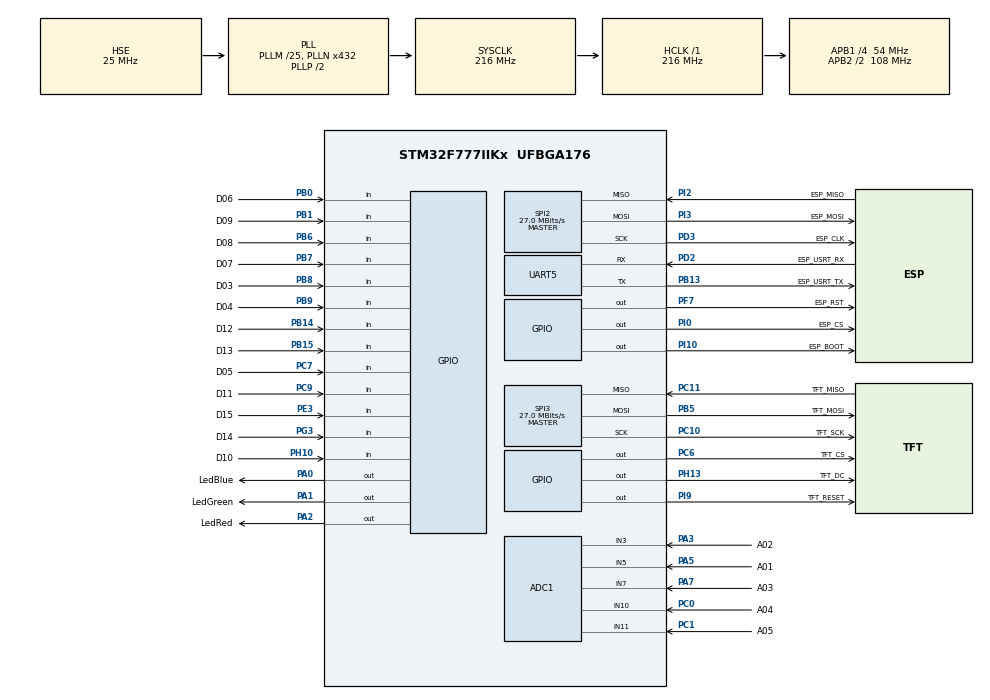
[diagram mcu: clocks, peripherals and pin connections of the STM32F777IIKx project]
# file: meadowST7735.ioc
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ADC1.Channel-0\#ChannelRegularConversion=ADC_CHANNEL_5
ADC1.NbrOfConversionFlag=1
ADC1.Rank-0\#ChannelRegularConversion=1
ADC1.SamplingTime-0\#ChannelRegularConversion=ADC_SAMPLETIME_3CYCLES
ADC1.master=1
CORTEX_M7.ART_ACCLERATOR_ENABLE=1
CORTEX_M7.PREFETCH_ENABLE=0
Mcu.Family=STM32F7
Mcu.Name=STM32F777IIKx
Mcu.Package=UFBGA176
NVIC.PriorityGroup=NVIC_PRIORITYGROUP_4
PA0/WKUP.GPIO_Label=LedBlue
PA0/WKUP.Signal=GPIO_Output
PA1.GPIO_Label=LedGreen
PA1.Signal=GPIO_Output
PA13.Mode=Serial_Wire
PA13.Signal=SYS_JTMS-SWDIO
PA14.Mode=Serial_Wire
PA14.Signal=SYS_JTCK-SWCLK
PA2.GPIO_Label=LedRed
PA2.Signal=GPIO_Output
PA3.GPIO_Label=A02
PA3.Signal=ADCx_IN3
PA5.GPIO_Label=A01
PA5.Signal=ADCx_IN5
PA7.GPIO_Label=A03
PA7.Signal=ADCx_IN7
PB0.GPIO_Label=D06
PB0.Signal=GPIO_Input
PB1.GPIO_Label=D09
PB1.Signal=GPIO_Input
PB13.GPIO_Label=ESP_USRT_TX
PB13.Mode=Asynchronous
PB13.Signal=UART5_TX
PB14.GPIO_Label=D12
PB14.Signal=GPIO_Input
PB15.GPIO_Label=D13
PB15.Signal=GPIO_Input
PB5.GPIO_Label=TFT_MOSI
PB5.Mode=Full_Duplex_Master
PB5.Signal=SPI3_MOSI
PB6.GPIO_Label=D08
PB6.Signal=GPIO_Input
PB7.GPIO_Label=D07
PB7.Signal=GPIO_Input
PB8.GPIO_Label=D03
PB8.Signal=GPIO_Input
PB9.GPIO_Label=D04
PB9.Signal=GPIO_Input
PC0.GPIO_Label=A04
PC0.Signal=ADCx_IN10
PC1.GPIO_Label=A05
PC1.Signal=ADCx_IN11
PC10.GPIO_Label=TFT_SCK
PC10.Mode=Full_Duplex_Master
PC10.Signal=SPI3_SCK
PC11.GPIO_Label=TFT_MISO
PC11.Mode=Full_Duplex_Master
PC11.Signal=SPI3_MISO
PC6.GPIO_Label=TFT_CS
PC6.Signal=GPIO_Output
PC7.GPIO_Label=D05
PC7.Signal=GPIO_Input
PC9.GPIO_Label=D11
PC9.Signal=GPIO_Input
PD2.GPIO_Label=ESP_USRT_RX
PD2.Mode=Asynchronous
PD2.Signal=UART5_RX
PD3.GPIO_Label=ESP_CLK
PD3.Mode=Full_Duplex_Master
PD3.Signal=SPI2_SCK
PE3.GPIO_Label=D15
PE3.Signal=GPIO_Input
PF7.GPIO_Label=ESP_RST
PF7.Signal=GPIO_Output
PG3.GPIO_Label=D14
PG3.Signal=GPIO_Input
PH0/OSC_IN.Mode=HSE-External-Oscillator
PH0/OSC_IN.Signal=RCC_OSC_IN
PH1/OSC_OUT.Mode=HSE-External-Oscillator
PH1/OSC_OUT.Signal=RCC_OSC_OUT
PH10.GPIO_Label=D10
PH10.Signal=GPIO_Input
PH13.GPIO_Label=TFT_DC
PH13.Signal=GPIO_Output
PI0.GPIO_Label=ESP_CS
PI0.Signal=GPIO_Output
PI10.GPIO_Label=ESP_BOOT
PI10.Signal=GPIO_Output
PI2.GPIO_Label=ESP_MISO
PI2.Mode=Full_Duplex_Master
PI2.Signal=SPI2_MISO
PI3.GPIO_Label=ESP_MOSI
PI3.Mode=Full_Duplex_Master
PI3.Signal=SPI2_MOSI
PI9.GPIO_Label=TFT_RESET
PI9.Signal=GPIO_Output
ProjectManager.HeapSize=0x200
ProjectManager.StackSize=0x400
ProjectManager.TargetToolchain=STM32CubeIDE
RCC.AHBFreq_Value=216000000
RCC.APB1CLKDivider=RCC_HCLK_DIV4
RCC.APB1Freq_Value=54000000
RCC.APB1TimFreq_Value=108000000
RCC.APB2CLKDivider=RCC_HCLK_DIV2
RCC.APB2Freq_Value=108000000
RCC.APB2TimFreq_Value=216000000
RCC.CortexFreq_Value=216000000
RCC.HCLKFreq_Value=216000000
RCC.HSE_VALUE=25000000
RCC.HSI_VALUE=16000000
RCC.LSE_VALUE=32768
RCC.PLLM=25
RCC.PLLN=432
RCC.PLLSourceVirtual=RCC_PLLSOURCE_HSE
RCC.SYSCLKFreq_VALUE=216000000
RCC.SYSCLKSource=RCC_SYSCLKSOURCE_PLLCLK
RCC.USBFreq_Value=216000000
RCC.VCOOutputFreq_Value=432000000
SH.ADCx_IN10.0=ADC1_IN10,IN10
SH.ADCx_IN11.0=ADC1_IN11,IN11
SH.ADCx_IN3.0=ADC1_IN3,IN3
SH.ADCx_IN5.0=ADC1_IN5,IN5
SH.ADCx_IN7.0=ADC1_IN7,IN7
SPI2.BaudRatePrescaler=SPI_BAUDRATEPRESCALER_2
SPI2.CalculateBaudRate=27.0 MBits/s
SPI2.DataSize=SPI_DATASIZE_8BIT
SPI2.Direction=SPI_DIRECTION_2LINES
SPI2.Mode=SPI_MODE_MASTER
SPI2.VirtualType=VM_MASTER
SPI3.BaudRatePrescaler=SPI_BAUDRATEPRESCALER_2
SPI3.CalculateBaudRate=27.0 MBits/s
SPI3.DataSize=SPI_DATASIZE_8BIT
SPI3.Direction=SPI_DIRECTION_2LINES
SPI3.Mode=SPI_MODE_MASTER
SPI3.VirtualType=VM_MASTER
VP_CRC_VS_CRC.Mode=CRC_Activate
board=custom

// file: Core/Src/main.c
/* USER CODE BEGIN Header */
/**
  ******************************************************************************
  * @file           : main.c
  * @brief          : Main program body
  ******************************************************************************
  * @attention
  *
  * <h2><center>&copy; Copyright (c) 2021 STMicroelectronics.
  * All rights reserved.</center></h2>
  *
  * This software component is licensed by ST under BSD 3-Clause license,
  * the "License"; You may not use this file except in compliance with the
  * License. You may obtain a copy of the License at:
  *                        opensource.org/licenses/BSD-3-Clause
  *
  ******************************************************************************
  */
/* USER CODE END Header */
#include "main.h"

/* USER CODE BEGIN Includes */
#include "GUI.h"
#include "DIALOG.h"
/* USER CODE END Includes */

ADC_HandleTypeDef hadc1;

CRC_HandleTypeDef hcrc;

SPI_HandleTypeDef hspi2;
SPI_HandleTypeDef hspi3;

UART_HandleTypeDef huart5;

/* USER CODE BEGIN PV */
//extern const GUI_BITMAP bmlemmling_Cartoon_penguin_small;
//GUI_HSPRITE hSprite;
/* USER CODE END PV */

void SystemClock_Config(void);
static void MX_GPIO_Init(void);
static void MX_ADC1_Init(void);
static void MX_SPI2_Init(void);
static void MX_SPI3_Init(void);
static void MX_UART5_Init(void);
static void MX_CRC_Init(void);

int main(void)
{

  /* MCU Configuration--------------------------------------------------------*/

  /* Reset of all peripherals, Initializes the Flash interface and the Systick. */
  HAL_Init();

  /* Configure the system clock */
  SystemClock_Config();

  /* Initialize all configured peripherals */
  MX_GPIO_Init();
  MX_ADC1_Init();
  MX_SPI2_Init();
  MX_SPI3_Init();
  MX_UART5_Init();
  MX_CRC_Init();
  /* USER CODE BEGIN 2 */
  GUI_Init();

  GUI_SetBkColor(GUI_BLUE);
  GUI_Clear();
  GUI_SetFont(&GUI_Font20B_ASCII);
  GUI_SetColor(GUI_YELLOW);

  GUI_DispStringHCenterAt("ECET260", 80, 20);
  GUI_DispStringHCenterAt("Mel Dundas", 80, 50);

  //hSprite = GUI_DRAW_BITMAP_Create(&bmlemmling_Cartoon_penguin_small, 160-30,120-30);
  //GUI_DRAW_BITMAP_Create(&bmlemmling_Cartoon_penguin_small, 160-30,120-30);

  GUI_Exec();
  /* USER CODE END 2 */

  /* Infinite loop */
  /* USER CODE BEGIN WHILE */
  while (1)
  {
	  HAL_GPIO_WritePin(LedRed_GPIO_Port, LedRed_Pin, GPIO_PIN_SET);
	  HAL_Delay(200);
	  HAL_GPIO_WritePin(LedRed_GPIO_Port, LedRed_Pin, GPIO_PIN_RESET);
	  HAL_Delay(200);

    /* USER CODE END WHILE */

  }
}

void SystemClock_Config(void)
{
  RCC_OscInitTypeDef RCC_OscInitStruct = {0};
  RCC_ClkInitTypeDef RCC_ClkInitStruct = {0};
  RCC_PeriphCLKInitTypeDef PeriphClkInitStruct = {0};

  /** Configure the main internal regulator output voltage
  */
  __HAL_RCC_PWR_CLK_ENABLE();
  __HAL_PWR_VOLTAGESCALING_CONFIG(PWR_REGULATOR_VOLTAGE_SCALE1);
  /** Initializes the RCC Oscillators according to the specified parameters
  * in the RCC_OscInitTypeDef structure.
  */
  RCC_OscInitStruct.OscillatorType = RCC_OSCILLATORTYPE_HSE;
  RCC_OscInitStruct.HSEState = RCC_HSE_ON;
  RCC_OscInitStruct.PLL.PLLState = RCC_PLL_ON;
  RCC_OscInitStruct.PLL.PLLSource = RCC_PLLSOURCE_HSE;
  RCC_OscInitStruct.PLL.PLLM = 25;
  RCC_OscInitStruct.PLL.PLLN = 432;
  RCC_OscInitStruct.PLL.PLLP = RCC_PLLP_DIV2;
  RCC_OscInitStruct.PLL.PLLQ = 2;
  RCC_OscInitStruct.PLL.PLLR = 2;
  if (HAL_RCC_OscConfig(&RCC_OscInitStruct) != HAL_OK)
  {
    Error_Handler();
  }
  /** Activate the Over-Drive mode
  */
  if (HAL_PWREx_EnableOverDrive() != HAL_OK)
  {
    Error_Handler();
  }
  /** Initializes the CPU, AHB and APB buses clocks
  */
  RCC_ClkInitStruct.ClockType = RCC_CLOCKTYPE_HCLK|RCC_CLOCKTYPE_SYSCLK
                              |RCC_CLOCKTYPE_PCLK1|RCC_CLOCKTYPE_PCLK2;
  RCC_ClkInitStruct.SYSCLKSource = RCC_SYSCLKSOURCE_PLLCLK;
  RCC_ClkInitStruct.AHBCLKDivider = RCC_SYSCLK_DIV1;
  RCC_ClkInitStruct.APB1CLKDivider = RCC_HCLK_DIV4;
  RCC_ClkInitStruct.APB2CLKDivider = RCC_HCLK_DIV2;

  if (HAL_RCC_ClockConfig(&RCC_ClkInitStruct, FLASH_LATENCY_7) != HAL_OK)
  {
    Error_Handler();
  }
  PeriphClkInitStruct.PeriphClockSelection = RCC_PERIPHCLK_UART5;
  PeriphClkInitStruct.Uart5ClockSelection = RCC_UART5CLKSOURCE_PCLK1;
  if (HAL_RCCEx_PeriphCLKConfig(&PeriphClkInitStruct) != HAL_OK)
  {
    Error_Handler();
  }
}

static void MX_ADC1_Init(void)
{

  ADC_ChannelConfTypeDef sConfig = {0};

  /** Configure the global features of the ADC (Clock, Resolution, Data Alignment and number of conversion)
  */
  hadc1.Instance = ADC1;
  hadc1.Init.ClockPrescaler = ADC_CLOCK_SYNC_PCLK_DIV4;
  hadc1.Init.Resolution = ADC_RESOLUTION_12B;
  hadc1.Init.ScanConvMode = ADC_SCAN_DISABLE;
  hadc1.Init.ContinuousConvMode = DISABLE;
  hadc1.Init.DiscontinuousConvMode = DISABLE;
  hadc1.Init.ExternalTrigConvEdge = ADC_EXTERNALTRIGCONVEDGE_NONE;
  hadc1.Init.ExternalTrigConv = ADC_SOFTWARE_START;
  hadc1.Init.DataAlign = ADC_DATAALIGN_RIGHT;
  hadc1.Init.NbrOfConversion = 1;
  hadc1.Init.DMAContinuousRequests = DISABLE;
  hadc1.Init.EOCSelection = ADC_EOC_SINGLE_CONV;
  if (HAL_ADC_Init(&hadc1) != HAL_OK)
  {
    Error_Handler();
  }
  /** Configure for the selected ADC regular channel its corresponding rank in the sequencer and its sample time.
  */
  sConfig.Channel = ADC_CHANNEL_5;
  sConfig.Rank = ADC_REGULAR_RANK_1;
  sConfig.SamplingTime = ADC_SAMPLETIME_3CYCLES;
  if (HAL_ADC_ConfigChannel(&hadc1, &sConfig) != HAL_OK)
  {
    Error_Handler();
  }

}

static void MX_CRC_Init(void)
{

  hcrc.Instance = CRC;
  hcrc.Init.DefaultPolynomialUse = DEFAULT_POLYNOMIAL_ENABLE;
  hcrc.Init.DefaultInitValueUse = DEFAULT_INIT_VALUE_ENABLE;
  hcrc.Init.InputDataInversionMode = CRC_INPUTDATA_INVERSION_NONE;
  hcrc.Init.OutputDataInversionMode = CRC_OUTPUTDATA_INVERSION_DISABLE;
  hcrc.InputDataFormat = CRC_INPUTDATA_FORMAT_BYTES;
  if (HAL_CRC_Init(&hcrc) != HAL_OK)
  {
    Error_Handler();
  }

}

static void MX_SPI2_Init(void)
{

  /* SPI2 parameter configuration*/
  hspi2.Instance = SPI2;
  hspi2.Init.Mode = SPI_MODE_MASTER;
  hspi2.Init.Direction = SPI_DIRECTION_2LINES;
  hspi2.Init.DataSize = SPI_DATASIZE_8BIT;
  hspi2.Init.CLKPolarity = SPI_POLARITY_LOW;
  hspi2.Init.CLKPhase = SPI_PHASE_1EDGE;
  hspi2.Init.NSS = SPI_NSS_SOFT;
  hspi2.Init.BaudRatePrescaler = SPI_BAUDRATEPRESCALER_2;
  hspi2.Init.FirstBit = SPI_FIRSTBIT_MSB;
  hspi2.Init.TIMode = SPI_TIMODE_DISABLE;
  hspi2.Init.CRCCalculation = SPI_CRCCALCULATION_DISABLE;
  hspi2.Init.CRCPolynomial = 7;
  hspi2.Init.CRCLength = SPI_CRC_LENGTH_DATASIZE;
  hspi2.Init.NSSPMode = SPI_NSS_PULSE_ENABLE;
  if (HAL_SPI_Init(&hspi2) != HAL_OK)
  {
    Error_Handler();
  }

}

static void MX_SPI3_Init(void)
{

  /* SPI3 parameter configuration*/
  hspi3.Instance = SPI3;
  hspi3.Init.Mode = SPI_MODE_MASTER;
  hspi3.Init.Direction = SPI_DIRECTION_2LINES;
  hspi3.Init.DataSize = SPI_DATASIZE_8BIT;
  hspi3.Init.CLKPolarity = SPI_POLARITY_LOW;
  hspi3.Init.CLKPhase = SPI_PHASE_1EDGE;
  hspi3.Init.NSS = SPI_NSS_SOFT;
  hspi3.Init.BaudRatePrescaler = SPI_BAUDRATEPRESCALER_2;
  hspi3.Init.FirstBit = SPI_FIRSTBIT_MSB;
  hspi3.Init.TIMode = SPI_TIMODE_DISABLE;
  hspi3.Init.CRCCalculation = SPI_CRCCALCULATION_DISABLE;
  hspi3.Init.CRCPolynomial = 7;
  hspi3.Init.CRCLength = SPI_CRC_LENGTH_DATASIZE;
  hspi3.Init.NSSPMode = SPI_NSS_PULSE_ENABLE;
  if (HAL_SPI_Init(&hspi3) != HAL_OK)
  {
    Error_Handler();
  }

}

static void MX_UART5_Init(void)
{

  huart5.Instance = UART5;
  huart5.Init.BaudRate = 115200;
  huart5.Init.WordLength = UART_WORDLENGTH_8B;
  huart5.Init.StopBits = UART_STOPBITS_1;
  huart5.Init.Parity = UART_PARITY_NONE;
  huart5.Init.Mode = UART_MODE_TX_RX;
  huart5.Init.HwFlowCtl = UART_HWCONTROL_NONE;
  huart5.Init.OverSampling = UART_OVERSAMPLING_16;
  huart5.Init.OneBitSampling = UART_ONE_BIT_SAMPLE_DISABLE;
  huart5.AdvancedInit.AdvFeatureInit = UART_ADVFEATURE_NO_INIT;
  if (HAL_UART_Init(&huart5) != HAL_OK)
  {
    Error_Handler();
  }

}

static void MX_GPIO_Init(void)
{
  GPIO_InitTypeDef GPIO_InitStruct = {0};

  /* GPIO Ports Clock Enable */
  __HAL_RCC_GPIOE_CLK_ENABLE();
  __HAL_RCC_GPIOB_CLK_ENABLE();
  __HAL_RCC_GPIOA_CLK_ENABLE();
  __HAL_RCC_GPIOC_CLK_ENABLE();
  __HAL_RCC_GPIOI_CLK_ENABLE();
  __HAL_RCC_GPIOD_CLK_ENABLE();
  __HAL_RCC_GPIOH_CLK_ENABLE();
  __HAL_RCC_GPIOF_CLK_ENABLE();
  __HAL_RCC_GPIOG_CLK_ENABLE();

  /*Configure GPIO pin Output Level */
  HAL_GPIO_WritePin(GPIOI, TFT_RESET_Pin|ESP_BOOT_Pin|ESP_CS_Pin, GPIO_PIN_RESET);

  /*Configure GPIO pin Output Level */
  HAL_GPIO_WritePin(TFT_DC_GPIO_Port, TFT_DC_Pin, GPIO_PIN_RESET);

  /*Configure GPIO pin Output Level */
  HAL_GPIO_WritePin(TFT_CS_GPIO_Port, TFT_CS_Pin, GPIO_PIN_RESET);

  /*Configure GPIO pin Output Level */
  HAL_GPIO_WritePin(ESP_RST_GPIO_Port, ESP_RST_Pin, GPIO_PIN_RESET);

  /*Configure GPIO pin Output Level */
  HAL_GPIO_WritePin(GPIOA, LedGreen_Pin|LedBlue_Pin|LedRed_Pin, GPIO_PIN_RESET);

  /*Configure GPIO pin : D15_Pin */
  GPIO_InitStruct.Pin = D15_Pin;
  GPIO_InitStruct.Mode = GPIO_MODE_INPUT;
  GPIO_InitStruct.Pull = GPIO_NOPULL;
  HAL_GPIO_Init(D15_GPIO_Port, &GPIO_InitStruct);

  /*Configure GPIO pins : D03_Pin D04_Pin D07_Pin D08_Pin
                           D09_Pin D06_Pin D12_Pin D13_Pin */
  GPIO_InitStruct.Pin = D03_Pin|D04_Pin|D07_Pin|D08_Pin
                          |D09_Pin|D06_Pin|D12_Pin|D13_Pin;
  GPIO_InitStruct.Mode = GPIO_MODE_INPUT;
  GPIO_InitStruct.Pull = GPIO_NOPULL;
  HAL_GPIO_Init(GPIOB, &GPIO_InitStruct);

  /*Configure GPIO pins : TFT_RESET_Pin ESP_BOOT_Pin ESP_CS_Pin */
  GPIO_InitStruct.Pin = TFT_RESET_Pin|ESP_BOOT_Pin|ESP_CS_Pin;
  GPIO_InitStruct.Mode = GPIO_MODE_OUTPUT_PP;
  GPIO_InitStruct.Pull = GPIO_NOPULL;
  GPIO_InitStruct.Speed = GPIO_SPEED_FREQ_LOW;
  HAL_GPIO_Init(GPIOI, &GPIO_InitStruct);

  /*Configure GPIO pin : TFT_DC_Pin */
  GPIO_InitStruct.Pin = TFT_DC_Pin;
  GPIO_InitStruct.Mode = GPIO_MODE_OUTPUT_PP;
  GPIO_InitStruct.Pull = GPIO_NOPULL;
  GPIO_InitStruct.Speed = GPIO_SPEED_FREQ_LOW;
  HAL_GPIO_Init(TFT_DC_GPIO_Port, &GPIO_InitStruct);

  /*Configure GPIO pins : D11_Pin D05_Pin */
  GPIO_InitStruct.Pin = D11_Pin|D05_Pin;
  GPIO_InitStruct.Mode = GPIO_MODE_INPUT;
  GPIO_InitStruct.Pull = GPIO_NOPULL;
  HAL_GPIO_Init(GPIOC, &GPIO_InitStruct);

  /*Configure GPIO pin : TFT_CS_Pin */
  GPIO_InitStruct.Pin = TFT_CS_Pin;
  GPIO_InitStruct.Mode = GPIO_MODE_OUTPUT_PP;
  GPIO_InitStruct.Pull = GPIO_NOPULL;
  GPIO_InitStruct.Speed = GPIO_SPEED_FREQ_LOW;
  HAL_GPIO_Init(TFT_CS_GPIO_Port, &GPIO_InitStruct);

  /*Configure GPIO pin : ESP_RST_Pin */
  GPIO_InitStruct.Pin = ESP_RST_Pin;
  GPIO_InitStruct.Mode = GPIO_MODE_OUTPUT_PP;
  GPIO_InitStruct.Pull = GPIO_NOPULL;
  GPIO_InitStruct.Speed = GPIO_SPEED_FREQ_LOW;
  HAL_GPIO_Init(ESP_RST_GPIO_Port, &GPIO_InitStruct);

  /*Configure GPIO pin : D14_Pin */
  GPIO_InitStruct.Pin = D14_Pin;
  GPIO_InitStruct.Mode = GPIO_MODE_INPUT;
  GPIO_InitStruct.Pull = GPIO_NOPULL;
  HAL_GPIO_Init(D14_GPIO_Port, &GPIO_InitStruct);

  /*Configure GPIO pin : D10_Pin */
  GPIO_InitStruct.Pin = D10_Pin;
  GPIO_InitStruct.Mode = GPIO_MODE_INPUT;
  GPIO_InitStruct.Pull = GPIO_NOPULL;
  HAL_GPIO_Init(D10_GPIO_Port, &GPIO_InitStruct);

  /*Configure GPIO pins : LedGreen_Pin LedBlue_Pin LedRed_Pin */
  GPIO_InitStruct.Pin = LedGreen_Pin|LedBlue_Pin|LedRed_Pin;
  GPIO_InitStruct.Mode = GPIO_MODE_OUTPUT_PP;
  GPIO_InitStruct.Pull = GPIO_NOPULL;
  GPIO_InitStruct.Speed = GPIO_SPEED_FREQ_LOW;
  HAL_GPIO_Init(GPIOA, &GPIO_InitStruct);

}

void Error_Handler(void)
{
  __disable_irq();
  while (1)
  {
  }
}

/************************ (C) COPYRIGHT STMicroelectronics *****END OF FILE****/
